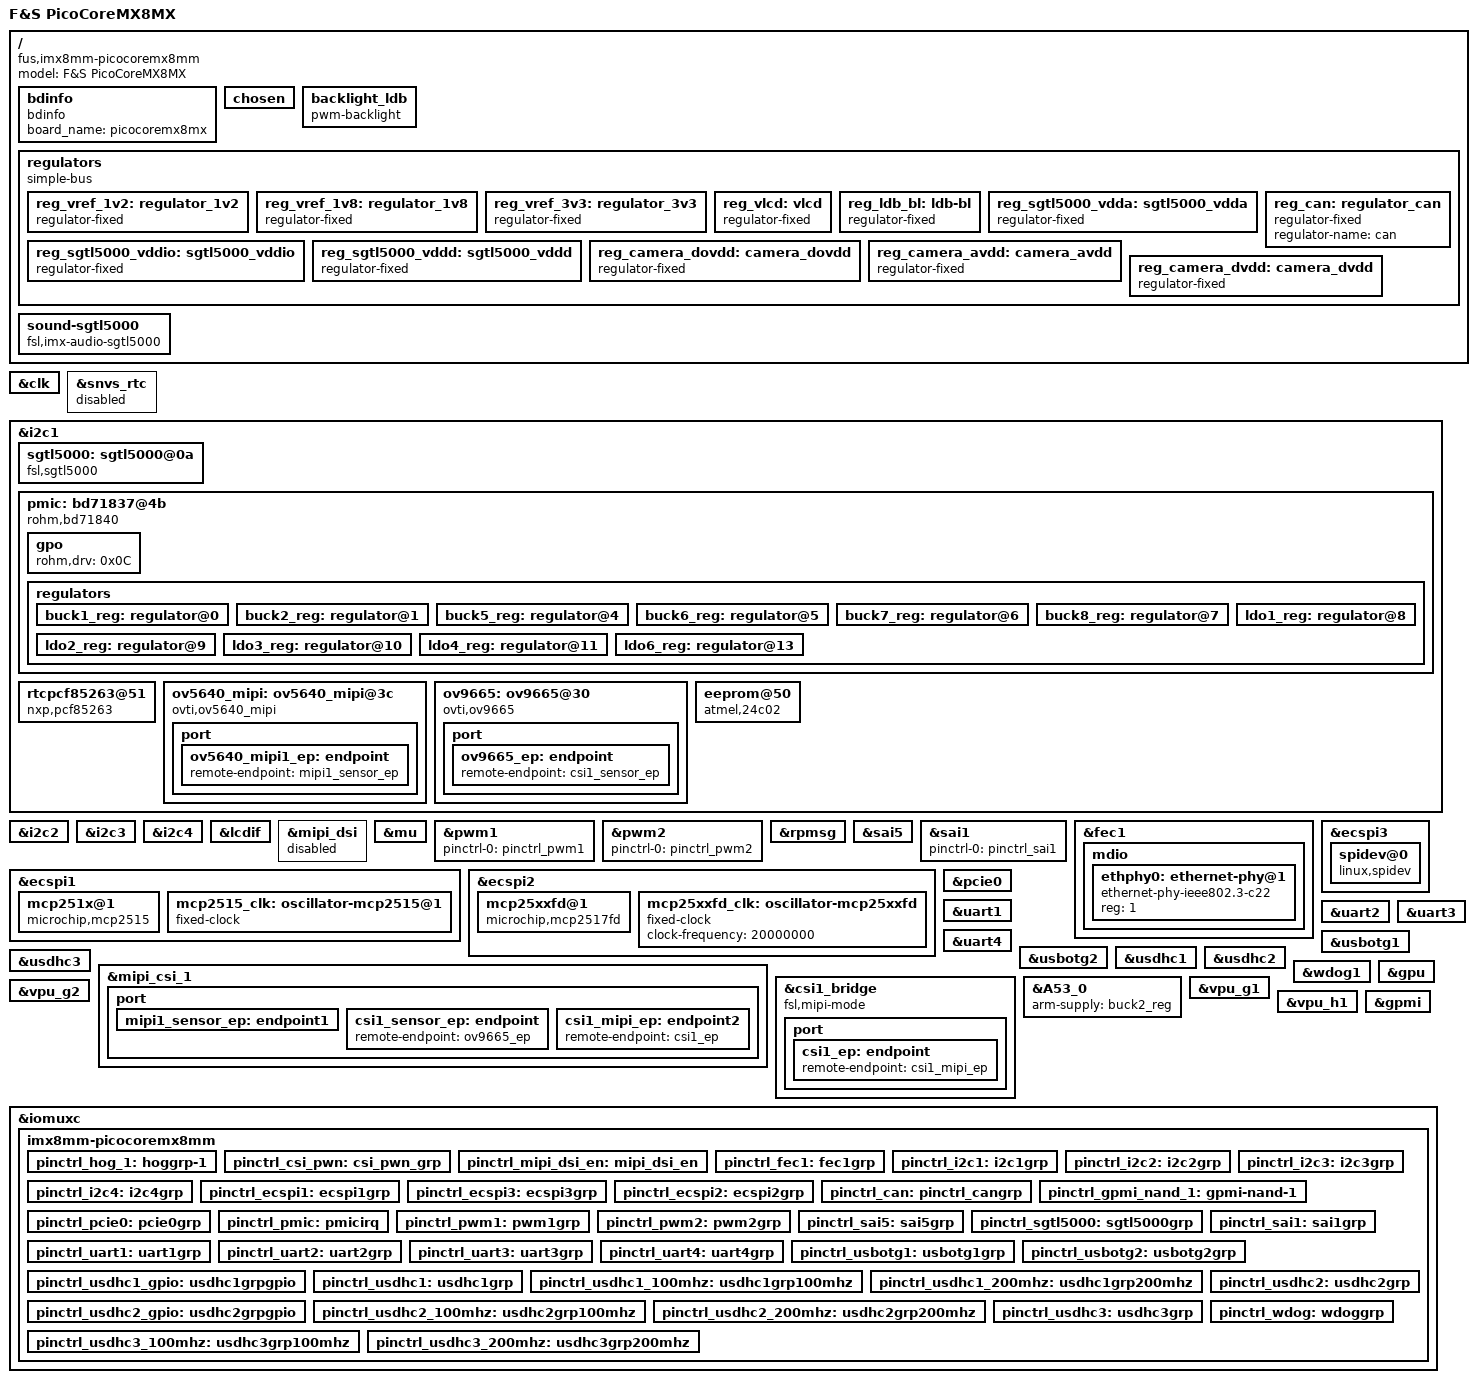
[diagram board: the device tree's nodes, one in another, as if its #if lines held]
/*
 * Copyright 2018 NXP
 *
 * This program is free software; you can redistribute it and/or
 * modify it under the terms of the GNU General Public License
 * as published by the Free Software Foundation; either version 2
 * of the License, or (at your option) any later version.
 *
 * This program is distributed in the hope that it will be useful,
 * but WITHOUT ANY WARRANTY; without even the implied warranty of
 * MERCHANTABILITY or FITNESS FOR A PARTICULAR PURPOSE.  See the
 * GNU General Public License for more details.
 */

/*
 * Copyright (C) 2019 F&S Elektronik Systeme GmbH
 *
 * This program is free software; you can redistribute it and/or modify
 * it under the terms of the GNU General Public License version 2 as
 * published by the Free Software Foundation.
 */

/dts-v1/;

/* Set board revision as 3-digit number, e.g. 110 for board rev. 1.10 */
#define CONFIG_PICOCOREMX8MX_BOARD_REVISION	100

/* MIPI DSI */
#define CONFIG_PICOCOREMX8MX_MIPI_DSI
//#define CONFIG_PICOCOREMX8MX_MIPI_DSI_LVDS

/* On-board NAND */
#define CONFIG_PICOCOREMX8MX_NAND

/* On-board eMMC */
//#define CONFIG_PICOCOREMX8MX_EMMC

/* Network */
//###: TODO Check how it works with Switch
//#define CONFIG_PICOCOREMX8MX_ETH

/* USB */
#define CONFIG_PICOCOREMX8MX_USB_OTG1
#define CONFIG_PICOCOREMX8MX_USB_HOST

/* EEPROM - default not mounted */
//#define CONFIG_PICOCOREMX8MX_EEPROM

/* PCIe */
#define CONFIG_PICOCOREMX8MX_PCIE

/* CAN - default not mounted */
//#define CONFIG_PICOCOREMX8MX_CAN

/* I2C */
#define CONFIG_PICOCOREMX8MX_I2C_A
#define CONFIG_PICOCOREMX8MX_I2C_B
#define CONFIG_PICOCOREMX8MX_I2C_C
#define CONFIG_PICOCOREMX8MX_I2C_D
//#define CONFIG_PICOCOREMX8MX_I2C_D_A71CH

/* PWM and backlight brightness */
#define CONFIG_PICOCOREMX8MX_PWM_A
#define CONFIG_PICOCOREMX8MX_BL_CTRL

/* UART_A - UART1 */
#define CONFIG_PICOCOREMX8MX_UART_A
#define CONFIG_PICOCOREMX8MX_UART_A_RTSCTS

/* UART_B - UART2 */
#define CONFIG_PICOCOREMX8MX_UART_B
#define CONFIG_PICOCOREMX8MX_UART_B_RTSCTS

/* UART_C - UART4 */
#define CONFIG_PICOCOREMX8MX_UART_C

/* UART_D - UART3 */
#define CONFIG_PICOCOREMX8MX_UART_D

#define CONFIG_PICOCOREMX8MX_SPI_A
/* HW option, only works if R89 = mounted, R82 = umounted */
//#define CONFIG_PICOCOREMX8MX_SPI_A_CAN_CONVERTER
#define CONFIG_PICOCOREMX8MX_SPI_B
#define CONFIG_PICOCOREMX8MX_SPI_C

/* Audio */
#define CONFIG_PICOCOREMX8MX_SGTL5000_AUDIO
//#define CONFIG_PICOCOREMX8MX_AUDIO_2

/* External RTC - default not mounted */
//#define CONFIG_PICOCOREMX8MX_EXT_RTC

#define CONFIG_PICOCOREMX8MX_CAMERA

/* Camera on parallel CSI interface */
//#define CONFIG_PICOCOREMX8MX_PARALLEL_CAMERA

/* Camera on serial MIPI CSI interface */
#define CONFIG_PICOCOREMX8MX_SERIAL_CAMERA

/*
 * SD_A - External SD port with Card Detect (CD) and Write Protect (WP)
 * On picocoremx8mm SKIT: external port is Micro-SD card slot with CD but without WP
 */
#define CONFIG_PICOCOREMX8MX_SD_A
#define CONFIG_PICOCOREMX8MX_SD_A_CD
//#define CONFIG_PICOCOREMX8MX_SD_A_WP

/*
 * SD_B - External SD port with Card Detect (CD) and Write Protect (WP)
 * only available if WLAN is not equipped.
 */
#define CONFIG_PICOCOREMX8MX_SD_B
#define CONFIG_PICOCOREMX8MX_SD_B_CD
#define CONFIG_PICOCOREMX8MX_SD_B_WP

/* If NAND is equipped, eMMC is not available */
#ifdef CONFIG_PICOCOREMX8MX_NAND
#undef CONFIG_PICOCOREMX8MX_EMMC
#endif

#ifdef CONFIG_PICOCOREMX8MX_MIPI_DSI_LVDS
#undef CONFIG_PICOCOREMX8MX_SPI_A_CAN_CONVERTER
#endif

#include "../freescale/fsl-imx8mm.dtsi"
#include <dt-bindings/pwm/pwm.h>
#include <dt-bindings/rtc/nxp,pcf85263.h>

/ {
	model = "F&S PicoCoreMX8MX";
	compatible = "fus,imx8mm-picocoremx8mm", "fsl,imx8mm";

	/* -------------------- BOARD INFO -------------------- */
	bdinfo {
		compatible = "bdinfo";
		board_name = "picocoremx8mx";
	};

	chosen {
		bootargs = "console=ttymxc0,115200 earlycon=ec_imx6q,0x30860000,115200";
		stdout-path = &uart1;
	};

#ifdef CONFIG_PICOCOREMX8MX_BL_CTRL
	backlight_ldb {
		compatible = "pwm-backlight";
		#pwm-cells = <3>;
		pwms = <&pwm2 0 3000000 PWM_POLARITY_INVERTED>;
		power-supply = <&reg_ldb_bl>;
		brightness-levels = <0 1 5 10 18 28 41 56
				     73 92 113 137 163 192 222 255>;
		default-brightness-level = <4>;
		fb-names = "mxs-lcdif0";
	};
#endif

	regulators {
		compatible = "simple-bus";
		#address-cells = <1>;
		#size-cells = <0>;

		/* necessary for lcdif-tc35874-j070wvtc0211 */
		reg_vref_1v2: regulator_1v2 {
			compatible = "regulator-fixed";
			regulator-name = "vref-1V2";
			regulator-min-microvolt = <1200000>;
			regulator-max-microvolt = <1200000>;
			regulator-always-on;
		};

		reg_vref_1v8: regulator_1v8 {
			compatible = "regulator-fixed";
			regulator-name = "vref-1V8";
			regulator-min-microvolt = <1800000>;
			regulator-max-microvolt = <1800000>;
			regulator-always-on;
		};

		reg_vref_3v3: regulator_3v3 {
			compatible = "regulator-fixed";
			regulator-name = "vref-3V3";
			regulator-min-microvolt = <3300000>;
			regulator-max-microvolt = <3300000>;
			regulator-always-on;
		};

		/* LCD power on voltage */
		reg_vlcd: vlcd {
			compatible = "regulator-fixed";
			regulator-name = "VLCD";
			gpio = <&gpio5 1 GPIO_ACTIVE_HIGH>;
			regulator-min-microvolt = <3300000>;
			regulator-max-microvolt = <3300000>;
			enable-active-high;
		};

		reg_ldb_bl: ldb-bl {
			compatible = "regulator-fixed";
			regulator-name = "ldb-bl";
			gpio = <&gpio5 3 GPIO_ACTIVE_HIGH>;
			regulator-min-microvolt = <3300000>;
			regulator-max-microvolt = <3300000>;
			enable-active-high;
		};

#if 0
		reg_usb_otg1_vbus: usb_otg1_vbus {
			compatible = "regulator-fixed";
			regulator-name = "usb_otg1_vbus";
			regulator-min-microvolt = <5000000>;
			regulator-max-microvolt = <5000000>;
			gpio = <&gpio1 12 GPIO_ACTIVE_LOW>;
		};
#endif
#if 0
		reg_usb_otg2_vbus: usb_otg2_vbus {
			compatible = "regulator-fixed";
			regulator-name = "usb_otg1_vbus";
			regulator-min-microvolt = <5000000>;
			regulator-max-microvolt = <5000000>;
			gpio = <&gpio1 14 0>;
			enable-active-high;
		};
#endif

#ifdef CONFIG_PICOCOREMX8MX_SGTL5000_AUDIO
		/* SGTL5000 analog voltage */
		reg_sgtl5000_vdda: sgtl5000_vdda {
			compatible = "regulator-fixed";
			regulator-name = "VDDA-supply";
			regulator-min-microvolt = <3000000>;
			regulator-max-microvolt = <3000000>;
			regulator-always-on;
		};

		/* SGTL5000 I/O voltage */
		reg_sgtl5000_vddio: sgtl5000_vddio {
			compatible = "regulator-fixed";
			regulator-name = "VDDIO-supply";
			regulator-min-microvolt = <3300000>;
			regulator-max-microvolt = <3300000>;
			regulator-always-on;
		};

		/* SGTL5000 internal digital voltage */
		reg_sgtl5000_vddd: sgtl5000_vddd {
			compatible = "regulator-fixed";
			regulator-name = "VDDD-supply";
			regulator-min-microvolt = <1500000>;
			regulator-max-microvolt = <1500000>;
			regulator-always-on;
		};
#endif /* CONFIG_PICOCOREMX8MX_SGTL5000_AUDIO */

		/* CAN */
		reg_can: regulator_can {
			compatible = "regulator-fixed";
			regulator-name = "can";
		};

#ifdef CONFIG_PICOCOREMX8MX_CAMERA
		reg_camera_dovdd: camera_dovdd {
			compatible = "regulator-fixed";
			regulator-name = "DOVDD-supply";
			regulator-min-microvolt = <1800000>;
			regulator-max-microvolt = <1800000>;
		};

		reg_camera_avdd: camera_avdd {
			compatible = "regulator-fixed";
			regulator-name = "VAVDD-supply";
			regulator-min-microvolt = <2800000>;
			regulator-max-microvolt = <2800000>;
		};

		reg_camera_dvdd: camera_dvdd {
			compatible = "regulator-fixed";
			regulator-name = "DVDD-supply";
			regulator-min-microvolt = <1500000>;
			regulator-max-microvolt = <1500000>;
		};
#endif /* CONFIG_EFUSA9_CAMERA */
	};

#ifdef CONFIG_PICOCOREMX8MX_SGTL5000_AUDIO
	sound-sgtl5000 {
		compatible = "fsl,imx-audio-sgtl5000";
		cpu-dai = <&sai5>;
		audio-codec = <&sgtl5000>;
		model = "imx-sgtl5000";
		audio-routing =
			"LINE_IN", "Line In Jack",
//###			"MIC_IN", "Mic Jack",
//###			"Line Out Jack", "LINE_OUT",
			"Headphone Jack", "HP_OUT";
	};
#endif

};

&clk {
	assigned-clocks = <&clk IMX8MM_AUDIO_PLL1>, <&clk IMX8MM_AUDIO_PLL2>;
	assigned-clock-rates = <786432000>, <722534400>;
};

#ifdef CONFIG_PICOCOREMX8MX_EXT_RTC
&snvs_rtc {
	status = "disabled";
};
#endif

#ifdef CONFIG_PICOCOREMX8MX_I2C_D
&i2c1 {
	clock-frequency = <100000>;
	pinctrl-names = "default";
	pinctrl-0 = <&pinctrl_i2c1>;
	status = "okay";


#ifdef CONFIG_PICOCOREMX8MX_SGTL5000_AUDIO
	sgtl5000: sgtl5000@0a {
		compatible = "fsl,sgtl5000";
		/* MCLK is needed for i2c sgtl driver */
		pinctrl-names = "default";
		pinctrl-0 = <&pinctrl_sgtl5000>;
		reg = <0x0a>;
		mono2both;
		clocks = <&clk IMX8MM_CLK_SAI5_ROOT>;
		VDDA-supply = <&reg_sgtl5000_vdda>;
		VDDIO-supply = <&reg_sgtl5000_vddio>;
		VDDD-supply = <&reg_sgtl5000_vddd>;
	};
#endif

	/* PMIC */
	pmic: bd71837@4b {
		reg = <0x4b>;
		compatible = "rohm,bd71840", "rohm,bd71837";
		/* PMIC BD71837 PMIC_nINT GPIO3_IO24 */
		pinctrl-0 = <&pinctrl_pmic>;
		gpio_intr = <&gpio1 10 GPIO_ACTIVE_LOW>;

		gpo {
			rohm,drv = <0x0C>;	/* 0b0000_1100 all gpos with cmos output mode */
		};

		regulators {
			#address-cells = <1>;
			#size-cells = <0>;

			bd71837,pmic-buck2-uses-i2c-dvs;
			bd71837,pmic-buck2-dvs-voltage = <1000000>, <900000>, <0>; /* VDD_ARM: Run-Idle */

			buck1_reg: regulator@0 {
				reg = <0>;
				regulator-compatible = "buck1";
				regulator-min-microvolt = <700000>;
				regulator-max-microvolt = <1300000>;
				regulator-boot-on;
				regulator-always-on;
				regulator-ramp-delay = <1250>;
			};

			buck2_reg: regulator@1 {
				reg = <1>;
				regulator-compatible = "buck2";
				regulator-min-microvolt = <700000>;
				regulator-max-microvolt = <1300000>;
				regulator-boot-on;
				regulator-always-on;
				regulator-ramp-delay = <1250>;
			};
#if 0
			buck3_reg: regulator@2 {
				reg = <2>;
				regulator-compatible = "buck3";
				regulator-min-microvolt = <700000>;
				regulator-max-microvolt = <1300000>;
			};

			buck4_reg: regulator@3 {
				reg = <3>;
				regulator-compatible = "buck4";
				regulator-min-microvolt = <700000>;
				regulator-max-microvolt = <1300000>;
			};
#endif
			buck5_reg: regulator@4 {
				reg = <4>;
				regulator-compatible = "buck5";
				regulator-min-microvolt = <700000>;
				regulator-max-microvolt = <1350000>;
				regulator-boot-on;
				regulator-always-on;
			};

			buck6_reg: regulator@5 {
				reg = <5>;
				regulator-compatible = "buck6";
				regulator-min-microvolt = <2600000>;
				regulator-max-microvolt = <3300000>;
				regulator-boot-on;
				regulator-always-on;
			};

			buck7_reg: regulator@6 {
				reg = <6>;
				regulator-compatible = "buck7";
				regulator-min-microvolt = <1500000>;
				regulator-max-microvolt = <1605000>;
				regulator-boot-on;
				regulator-always-on;
			};

			buck8_reg: regulator@7 {
				reg = <7>;
				regulator-compatible = "buck8";
				regulator-min-microvolt = <800000>;
				regulator-max-microvolt = <1400000>;
				regulator-boot-on;
				regulator-always-on;
			};

			ldo1_reg: regulator@8 {
				reg = <8>;
				regulator-compatible = "ldo1";
				regulator-min-microvolt = <1600000>;
				regulator-max-microvolt = <1900000>;
				regulator-boot-on;
				regulator-always-on;
			};

			ldo2_reg: regulator@9 {
				reg = <9>;
				regulator-compatible = "ldo2";
				regulator-min-microvolt = <800000>;
				regulator-max-microvolt = <900000>;
				regulator-boot-on;
				regulator-always-on;
			};

			ldo3_reg: regulator@10 {
				reg = <10>;
				regulator-compatible = "ldo3";
				regulator-min-microvolt = <1800000>;
				regulator-max-microvolt = <3300000>;
				regulator-boot-on;
				regulator-always-on;
			};

			ldo4_reg: regulator@11 {
				reg = <11>;
				regulator-compatible = "ldo4";
				regulator-min-microvolt = <900000>;
				regulator-max-microvolt = <1800000>;
				regulator-boot-on;
				regulator-always-on;
			};

			ldo6_reg: regulator@13 {
				reg = <13>;
				regulator-compatible = "ldo6";
				regulator-min-microvolt = <900000>;
				regulator-max-microvolt = <1800000>;
				regulator-boot-on;
				regulator-always-on;
			};
		};
	};

#ifdef CONFIG_PICOCOREMX8MX_EXT_RTC
	rtcpcf85263@51 {
		compatible = "nxp,pcf85263";
		reg = <0x51>;
		clock-out = <PCF85263_CLK_OUT_32p768kHz>;

		quartz-load-capacitance = <PCF85263_QUARTZCAP_12p5pF>;
		quartz-drive-strength = <PCF85263_QUARTZDRIVE_LOW>;
	};
#endif

#ifdef CONFIG_PICOCOREMX8MX_SERIAL_CAMERA
	ov5640_mipi: ov5640_mipi@3c {
		compatible = "ovti,ov5640_mipi";
		reg = <0x3c>;
		status = "okay";
		pinctrl-names = "default";
		pinctrl-0 = <&pinctrl_csi_pwn>;
		clocks = <&clk IMX8MM_CLK_DUMMY>;
		clock-names = "csi_mclk";
		DOVDD-supply = <&reg_camera_dovdd>; /* 1.8v */
		AVDD-supply = <&reg_camera_avdd>;  /* 2.8v, rev C board is VGEN3
						rev B board is VGEN5 */
		DVDD-supply = <&reg_camera_dvdd>;  /* 1.5v*/
		csi_id = <0>;
		pwn-gpios = <&gpio1 0 GPIO_ACTIVE_LOW>;
		mclk = <24000000>;
		mclk_source = <0>;
		port {
			ov5640_mipi1_ep: endpoint {
				remote-endpoint = <&mipi1_sensor_ep>;
			};
		};
	};
#endif

#ifdef CONFIG_PICOCOREMX8MX_PARALLEL_CAMERA
	ov9665: ov9665@30 {
		compatible = "ovti,ov9665";
		reg = <0x30>;
		pinctrl-names = "default";
		pinctrl-0 = <&pinctrl_csi_pwn>;
		clocks = <&clks IMX8MM_CLK_DUMMY>;
		clock-names = "csi_mclk";
		DOVDD-supply = <&reg_camera_dovdd>;	/* 1.8v */
		AVDD-supply = <&reg_camera_avdd>;	/* 2.8v */
		DVDD-supply = <&reg_camera_dvdd>;	/* 1.5v */
		pwn-gpios = <&gpio1 0 GPIO_ACTIVE_LOW>;
		//rst-gpios = <&gpio3 27 GPIO_ACTIVE_HIGH>;
		csi_id = <0>;
		mclk = <24000000>;
		mclk_source = <0>;
		port {
			ov9665_ep: endpoint {
				remote-endpoint = <&csi1_sensor_ep>;
			};
		};
	};
#endif

#ifdef CONFIG_PICOCOREMX8MX_EEPROM
	/* EEPROM */
	eeprom@50 {
		compatible = "atmel,24c02";
		reg = <0x50>;
		pagesize = <8>;
	};
#endif

	/* ### TODO: implement root of trust A71CH-SDS */
};
#endif

#ifdef CONFIG_PICOCOREMX8MX_I2C_B
&i2c2 {
	clock-frequency = <100000>;
	pinctrl-names = "default";
	pinctrl-0 = <&pinctrl_i2c2>;
	status = "okay";
};
#endif

#ifdef CONFIG_PICOCOREMX8MX_I2C_C
&i2c3 {
	clock-frequency = <100000>;
	pinctrl-names = "default";
	pinctrl-0 = <&pinctrl_i2c3>;
	status = "okay";

	/* PCIe */

};
#endif

#ifdef CONFIG_PICOCOREMX8MX_I2C_A
&i2c4 {
	clock-frequency = <100000>;
	pinctrl-names = "default";
	pinctrl-0 = <&pinctrl_i2c4>;
	status = "okay";
};
#endif

&lcdif {
	status = "okay";
};

#ifdef CONFIG_PICOCOREMX8MX_MIPI_DSI
&mipi_dsi {
	status = "disabled";
};
#endif

&mu {
	status = "okay";
};

#ifdef CONFIG_PICOCOREMX8MX_PWM_A
&pwm1 {
	pinctrl-names = "default";
	pinctrl-0 = <&pinctrl_pwm1>;
	status = "okay";
};
#endif

#ifdef CONFIG_PICOCOREMX8MX_BL_CTRL
&pwm2 {
	pinctrl-names = "default";
	pinctrl-0 = <&pinctrl_pwm2>;
	status = "okay";
};
#endif

&rpmsg{
	/*
	 * 64K for one rpmsg instance:
	 * --0xb8000000~0xb800ffff: pingpong
	 */
	vdev-nums = <1>;
	reg = <0x0 0xb8000000 0x0 0x10000>;
	status = "okay";
};

#ifdef CONFIG_PICOCOREMX8MX_SGTL5000_AUDIO
&sai5 {
	#sound-dai-cells = <0>;
	pinctrl-names = "default";
	pinctrl-0 = <&pinctrl_sai5>;
	assigned-clocks = <&clk IMX8MM_CLK_SAI5>;
	assigned-clock-parents = <&clk IMX8MM_AUDIO_PLL1_OUT>;
	assigned-clock-rates = <24576000>;

	status = "okay";
};

#endif

#ifdef CONFIG_PICOCOREMX8MX_AUDIO_2
&sai1 {
	pinctrl-names = "default";
	pinctrl-0 = <&pinctrl_sai1>;
	status = "okay";
};
#endif

#ifdef CONFIG_PICOCOREMX8MX_ETH
&fec1 {
	pinctrl-names = "default";
	pinctrl-0 = <&pinctrl_fec1>;
	phy-mode = "rgmii-id";
	phy-handle = <&ethphy0>;
	fsl,magic-packet;
	status = "okay";

	mdio {
		#address-cells = <1>;
		#size-cells = <0>;

		ethphy0: ethernet-phy@1 {
			compatible = "ethernet-phy-ieee802.3-c22";
			reg = <1>;
		};
	};
};

#endif

#ifdef CONFIG_PICOCOREMX8MX_SPI_A
&ecspi1 {
	#address-cells = <1>;
	#size-cells = <0>;
	pinctrl-names = "default";
	pinctrl-0 = <&pinctrl_ecspi1>;
	fsl,spi-num-chipselects = <1>;
	cs-gpios = <&gpio5 9 GPIO_ACTIVE_LOW>;
	status = "okay";

#ifdef CONFIG_PICOCOREMX8MX_SPI_A_CAN_CONVERTER
	mcp251x@1 {
		compatible = "microchip,mcp2515";
		reg = <0>;
		clocks = <&mcp2515_clk>;
		interrupt-parent = <&gpio1>;
		interrupts = <4 IRQ_TYPE_EDGE_FALLING>;
		spi-max-frequency = <10000000>;
		status = "okay";
	};

	mcp2515_clk: oscillator-mcp2515@1 {
		compatible = "fixed-clock";
		reg = <1>;
		#clock-cells = <0>;
		clock-frequency = <20000000>; //20MHz
		};
#else
	spidev@0 {
		compatible = "linux,spidev";
		spi-max-frequency = <20000000>;
		reg = <0>;
		status = "okay";
	};
#endif
};
#endif

#ifdef CONFIG_PICOCOREMX8MX_SPI_B
&ecspi3 {
	#address-cells = <1>;
	#size-cells = <0>;
	pinctrl-names = "default";
	pinctrl-0 = <&pinctrl_ecspi3>;
	fsl,spi-num-chipselects = <1>;
	cs-gpios = <&gpio5 25 GPIO_ACTIVE_LOW>;
	status = "okay";

	spidev@0 {
		compatible = "linux,spidev";
		spi-max-frequency = <20000000>;
		reg = <0>;
		status = "okay";
	};
};
#endif

#ifdef CONFIG_PICOCOREMX8MX_SPI_C
&ecspi2 {
	pinctrl-names = "default";
	pinctrl-0 = <&pinctrl_ecspi2>;
	fsl,spi-num-chipselects = <1>;
	cs-gpios = <&gpio5 13 GPIO_ACTIVE_LOW>;
	status = "okay";

#ifdef CONFIG_PICOCOREMX8MX_CAN
	mcp25xxfd@1 {
		compatible = "microchip,mcp2517fd";
		reg = <0>;
		pinctrl-names = "default";
		pinctrl-0 = <&pinctrl_can>;
		spi-max-frequency = <10000000>;
		interrupt-parent = <&gpio4>;
		interrupts = <28 IRQ_TYPE_LEVEL_LOW>;
		clocks = <&mcp25xxfd_clk>;
		xceiver-supply = <&reg_can>;
		status = "okay";
	};
	mcp25xxfd_clk: oscillator-mcp25xxfd {
		compatible = "fixed-clock";
		#clock-cells = <0>;
		clock-frequency = <20000000>; //20MHz
	};
#endif
};
#endif

#ifdef CONFIG_PICOCOREMX8MX_PCIE
&pcie0 {
	pinctrl-names = "default";
	pinctrl-0 = <&pinctrl_pcie0>;
	reset-gpio = <&gpio3 19 GPIO_ACTIVE_LOW>;
	wake-gpio = <&gpio3 20 GPIO_ACTIVE_LOW>;
	ext_osc = <0>;
	status = "okay";
};
#endif

#ifdef CONFIG_PICOCOREMX8MX_UART_A
&uart1 {
	pinctrl-names = "default";
	pinctrl-0 = <&pinctrl_uart1>;
	assigned-clocks = <&clk IMX8MM_CLK_UART1>;
	assigned-clock-parents = <&clk IMX8MM_SYS_PLL1_80M>;
#ifdef CONFIG_PICOCOREMX8MX_UART_A_RTSCTS
	fsl,uart-has-rtscts;
#endif
	status = "okay";
};
#endif

#ifdef CONFIG_PICOCOREMX8MX_UART_B
&uart2 { /* console */
	pinctrl-names = "default";
	pinctrl-0 = <&pinctrl_uart2>;
	assigned-clocks = <&clk IMX8MM_CLK_UART2>;
	assigned-clock-parents = <&clk IMX8MM_SYS_PLL1_80M>;
#ifdef CONFIG_PICOCOREMX8MX_UART_B_RTSCTS
	fsl,uart-has-rtscts;
#endif
	status = "okay";
};
#endif

#ifdef CONFIG_PICOCOREMX8MX_UART_D
&uart3 {
	pinctrl-names = "default";
	pinctrl-0 = <&pinctrl_uart3>;
	assigned-clocks = <&clk IMX8MM_CLK_UART3>;
	assigned-clock-parents = <&clk IMX8MM_SYS_PLL1_80M>;
	status = "okay";
};
#endif

#ifdef CONFIG_PICOCOREMX8MX_UART_C
&uart4 {
	pinctrl-names = "default";
	pinctrl-0 = <&pinctrl_uart4>;
	assigned-clocks = <&clk IMX8MM_CLK_UART4>;
	assigned-clock-parents = <&clk IMX8MM_SYS_PLL1_80M>;
	status = "okay";
};
#endif

#ifdef CONFIG_PICOCOREMX8MX_USB_OTG1
&usbotg1 {
	dr_mode = "otg";
	pinctrl-names = "default";
	pinctrl-0 = <&pinctrl_usbotg1>;
	//vbus-supply = <&reg_usb_otg1_vbus>;
	picophy,pre-emp-curr-control = <3>;
	picophy,dc-vol-level-adjust = <7>;
	disable-over-current;
	status = "okay";
};
#endif

#ifdef CONFIG_PICOCOREMX8MX_USB_HOST
&usbotg2 {
	dr_mode = "host";
	pinctrl-names ="default";
	pinctrl-0 = <&pinctrl_usbotg2>;
	//vbus-supply = <&reg_usb_otg2_vbus>;
	pwr-active-high;
	disable-over-current;
	picophy,pre-emp-curr-control = <3>;
	picophy,dc-vol-level-adjust = <7>;
	status = "okay";
};
#endif

#ifdef CONFIG_PICOCOREMX8MX_SD_A
&usdhc1 {
	pinctrl-names = "default", "state_100mhz", "state_200mhz";
	pinctrl-0 = <&pinctrl_usdhc1>, <&pinctrl_usdhc1_gpio>;
	pinctrl-1 = <&pinctrl_usdhc1_100mhz>, <&pinctrl_usdhc1_gpio>;
	pinctrl-2 = <&pinctrl_usdhc1_200mhz>, <&pinctrl_usdhc1_gpio>;
	bus-width = <4>;
#ifdef CONFIG_PICOCOREMX8MX_SD_A_CD
	cd-gpios = <&gpio1 6 GPIO_ACTIVE_LOW>;
#else
	non-removable;
#endif
#ifdef CONFIG_PICOCOREMX8MX_SD_A_WP
	wp-gpios = <&gpio1 7 GPIO_ACTIVE_HIGH>;
#endif
	vmmc-supply = <&reg_vref_3v3>;
	vqmmc-supply = <&reg_vref_3v3>;
	pm-ignore-notify;
	keep-power-in-suspend;
	status = "okay";
};
#endif

/* WLAN */
#ifdef CONFIG_PICOCOREMX8MX_SD_B
&usdhc2 {
	pinctrl-names = "default", "state_100mhz", "state_200mhz";
	pinctrl-0 = <&pinctrl_usdhc2>, <&pinctrl_usdhc2_gpio>;
	pinctrl-1 = <&pinctrl_usdhc2_100mhz>, <&pinctrl_usdhc2_gpio>;
	pinctrl-2 = <&pinctrl_usdhc2_200mhz>, <&pinctrl_usdhc2_gpio>;
#ifdef CONFIG_PICOCOREMX8MX_SD_B_CD
	cd-gpios = <&gpio2 12 GPIO_ACTIVE_LOW>;
#else
	non-removable;
#endif
#ifdef CONFIG_PICOCOREMX8MX_SD_B_WP
	wp-gpios = <&gpio2 20 GPIO_ACTIVE_HIGH>;
#endif
	bus-width = <4>;
	vmmc-supply = <&reg_vref_3v3>;
	vqmmc-supply = <&reg_vref_3v3>;
	voltage-ranges = <3300 3300>;
	no-1-8-v;
	keep-power-in-suspend;
	status = "okay";
};
#endif

#ifdef CONFIG_PICOCOREMX8MX_EMMC
&usdhc3 {
	pinctrl-names = "default", "state_100mhz", "state_200mhz";
	pinctrl-0 = <&pinctrl_usdhc3>;
	pinctrl-1 = <&pinctrl_usdhc3_100mhz>;
	pinctrl-2 = <&pinctrl_usdhc3_200mhz>;
	bus-width = <8>;
	voltage-ranges = <3300 3300>;
	no-1-8-v;
	non-removable;
	status = "okay";
};
#endif

#ifdef CONFIG_PICOCOREMX8MX_SERIAL_CAMERA
&mipi_csi_1 {
	#address-cells = <1>;
	#size-cells = <0>;
	status = "okay";
	port {
		mipi1_sensor_ep: endpoint1 {
			remote-endpoint = <&ov5640_mipi1_ep>;
			data-lanes = <2>;
			csis-hs-settle = <13>;
			csis-clk-settle = <2>;
			csis-wclk;
		};

#ifdef CONFIG_PICOCOREMX8MX_PARALLEL_CAMERA
		csi1_sensor_ep: endpoint {
			remote-endpoint = <&ov9665_ep>;
		};
#endif

		csi1_mipi_ep: endpoint2 {
			remote-endpoint = <&csi1_ep>;
		};
	};
};

&csi1_bridge {
	fsl,mipi-mode;
	status = "okay";
	port {
		csi1_ep: endpoint {
			remote-endpoint = <&csi1_mipi_ep>;
		};
	};
};
#endif


&wdog1 {
	pinctrl-names = "default";
	pinctrl-0 = <&pinctrl_wdog>;
	fsl,ext-reset-output;
	status = "okay";
};

&A53_0 {
	arm-supply = <&buck2_reg>;
};

&gpu {
	status = "okay";
};

&vpu_g1 {
	status = "okay";
};

&vpu_g2 {
	status = "okay";
};

&vpu_h1 {
	status = "okay";
};

#ifdef CONFIG_PICOCOREMX8MX_NAND
&gpmi {
	pinctrl-names = "default";
	pinctrl-0 = <&pinctrl_gpmi_nand_1>;
	status = "okay";
	nand-on-flash-bbt;
};
#endif

&iomuxc {
	pinctrl-names = "default";

	imx8mm-picocoremx8mm {
		/* Pin configs that don't belong anywhere else */
		pinctrl_hog_1: hoggrp-1 {
			fsl,pins = <
				/* GPIO */
#ifndef CONFIG_PICOCOREMX8MX_MIPI_DSI_LVDS
#ifndef CONFIG_PICOCOREMX8MX_SPI_A_CAN_CONVERTER
				/* GPIO_J1_46 */
				MX8MM_IOMUXC_GPIO1_IO04_GPIO1_IO4		0x00104
#endif
				/* GPIO_J1_52 */
				MX8MM_IOMUXC_GPIO1_IO08_GPIO1_IO8		0x00104
				/* GPIO_J1_54 */
				MX8MM_IOMUXC_GPIO1_IO15_GPIO1_IO15		0x00104
#else
				/* LVDS_STBY */
				MX8MM_IOMUXC_GPIO1_IO04_GPIO1_IO4		0x00104
#endif
#ifndef CONFIG_PICOCOREMX8MX_SERIAL_CAMERA
				/* GPIO_J1_44 */
				MX8MM_IOMUXC_GPIO1_IO00_GPIO1_IO0		0x00104
#endif
#ifndef CONFIG_PICOCOREMX8MX_I2C_D_A71CH
				/* GPIO_J2_67 */
				MX8MM_IOMUXC_GPIO1_IO09_GPIO1_IO9		0x00104
#else
				/* I2C_A71CH_RST - default PD */
				MX8MM_IOMUXC_GPIO1_IO09_GPIO1_IO9		0x00104
#endif
#ifndef CONFIG_PICOCOREMX8MX_ETH
				/* GPIO_J2_77 */
				MX8MM_IOMUXC_GPIO1_IO11_GPIO1_IO11		0x00104
#endif
#ifndef CONFIG_PICOCOREMX8MX_CAN
				/* GPIO_J2_75 */
				MX8MM_IOMUXC_SAI3_RXFS_GPIO4_IO28		0x00104
				/* GPIO_J2_65 */
				MX8MM_IOMUXC_SAI2_MCLK_GPIO4_IO27		0x00104
				/* GPIO_J2_69 */
				MX8MM_IOMUXC_SAI2_TXC_GPIO4_IO25		0x00104
				/* GPIO_J2_73 */
				MX8MM_IOMUXC_SAI2_TXD0_GPIO4_IO26		0x00104
#endif
#ifndef CONFIG_PICOCOREMX8MX_AUDIO_2
				/* GPIO_J2_65 */
				MX8MM_IOMUXC_SAI1_MCLK_GPIO4_IO20		0x00104
				/* GPIO_J2_67 */
				MX8MM_IOMUXC_SAI1_TXFS_GPIO4_IO10		0x00104
				/* GPIO_J2_69 */
				MX8MM_IOMUXC_SAI1_TXC_GPIO4_IO11		0x00104
				/* GPIO_J2_73 */
				MX8MM_IOMUXC_SAI1_TXD0_GPIO4_IO12		0x00104
				/* GPIO_J2_77 */
				MX8MM_IOMUXC_SAI1_RXFS_GPIO4_IO0		0x00104
				/* GPIO_J2_79 */
				MX8MM_IOMUXC_SAI1_RXC_GPIO4_IO1			0x00104
				/* GPIO_J2_75 */
				MX8MM_IOMUXC_SAI1_RXD0_GPIO4_IO2		0x00104
#endif
				/* I2C_B_IRQn */
				MX8MM_IOMUXC_SAI3_MCLK_GPIO5_IO2		0x00144
				/* GPIO_J1_7, MIPI_RESET  */
				MX8MM_IOMUXC_GPIO1_IO01_GPIO1_IO1		0x00144
				/* BL_ON */
				MX8MM_IOMUXC_SPDIF_TX_GPIO5_IO3			0x00104
				/* GPIO_J1_2 */
				MX8MM_IOMUXC_GPIO1_IO13_GPIO1_IO13		0x00104
				/* VLCD_ON */
				MX8MM_IOMUXC_SAI3_TXD_GPIO5_IO1			0x00104
			>;
		};

#ifdef CONFIG_PICOCOREMX8MX_SERIAL_CAMERA
		pinctrl_csi_pwn: csi_pwn_grp {
			fsl,pins = <
				MX8MM_IOMUXC_GPIO1_IO00_GPIO1_IO0		0x00104
			>;
		};
#endif

#ifdef CONFIG_PICOCOREMX8MX_MIPI_DSI_LVDS
		pinctrl_mipi_dsi_en: mipi_dsi_en {
			fsl,pins = <
				/* LVDS RESET / TC358764 RST */
				MX8MM_IOMUXC_GPIO1_IO08_GPIO1_IO8			0x00016
				/* CLKO2 -> EXTCLK */
				MX8MM_IOMUXC_GPIO1_IO15_CCMSRCGPCMIX_CLKO2	0x00059
			>;
		};
#endif

#ifdef CONFIG_PICOCOREMX8MX_ETH
		pinctrl_fec1: fec1grp {
			fsl,pins = <
				MX8MM_IOMUXC_ENET_MDC_ENET1_MDC			0x00003
				MX8MM_IOMUXC_ENET_MDIO_ENET1_MDIO		0x00003
				MX8MM_IOMUXC_ENET_TD3_ENET1_RGMII_TD3		0x0001f
				MX8MM_IOMUXC_ENET_TD2_ENET1_RGMII_TD2		0x0001f
				MX8MM_IOMUXC_ENET_TD1_ENET1_RGMII_TD1		0x0001f
				MX8MM_IOMUXC_ENET_TD0_ENET1_RGMII_TD0		0x0001f
				MX8MM_IOMUXC_ENET_RD3_ENET1_RGMII_RD3		0x00091
				MX8MM_IOMUXC_ENET_RD2_ENET1_RGMII_RD2		0x00091
				MX8MM_IOMUXC_ENET_RD1_ENET1_RGMII_RD1		0x00091
				MX8MM_IOMUXC_ENET_RD0_ENET1_RGMII_RD0		0x00091
				MX8MM_IOMUXC_ENET_TXC_ENET1_RGMII_TXC		0x0001f
				MX8MM_IOMUXC_ENET_RXC_ENET1_RGMII_RXC		0x00091
				MX8MM_IOMUXC_ENET_RX_CTL_ENET1_RGMII_RX_CTL	0x00091
				MX8MM_IOMUXC_ENET_TX_CTL_ENET1_RGMII_TX_CTL	0x0001f
				/* reset */
				MX8MM_IOMUXC_GPIO1_IO05_GPIO1_IO5		0x00019
				/* ETH_SW_INTn */
				MX8MM_IOMUXC_GPIO1_IO11_GPIO1_IO11		0x00019
			>;
		};

#endif

#ifdef CONFIG_PICOCOREMX8MX_I2C_D
		pinctrl_i2c1: i2c1grp {
			fsl,pins = <
				MX8MM_IOMUXC_I2C1_SCL_I2C1_SCL			0x400001c3
				MX8MM_IOMUXC_I2C1_SDA_I2C1_SDA			0x400001c3
			>;
		};
#endif

#ifdef CONFIG_PICOCOREMX8MX_I2C_B
		pinctrl_i2c2: i2c2grp {
			fsl,pins = <
				MX8MM_IOMUXC_I2C2_SCL_I2C2_SCL			0x400001c3
				MX8MM_IOMUXC_I2C2_SDA_I2C2_SDA			0x400001c3
			>;
		};
#endif

#ifdef CONFIG_PICOCOREMX8MX_I2C_C
		pinctrl_i2c3: i2c3grp {
			fsl,pins = <
				MX8MM_IOMUXC_I2C3_SCL_I2C3_SCL			0x400001c3
				MX8MM_IOMUXC_I2C3_SDA_I2C3_SDA			0x400001c3
			>;
		};
#endif

#ifdef CONFIG_PICOCOREMX8MX_I2C_A
		pinctrl_i2c4: i2c4grp {
			fsl,pins = <
				MX8MM_IOMUXC_I2C4_SCL_I2C4_SCL			0x400001c3
				MX8MM_IOMUXC_I2C4_SDA_I2C4_SDA			0x400001c3
			>;
		};
#endif

#ifdef CONFIG_PICOCOREMX8MX_SPI_A
		pinctrl_ecspi1: ecspi1grp {
			fsl,pins = <
				MX8MM_IOMUXC_ECSPI1_SCLK_ECSPI1_SCLK		0x00082
				MX8MM_IOMUXC_ECSPI1_MOSI_ECSPI1_MOSI		0x00082
				MX8MM_IOMUXC_ECSPI1_MISO_ECSPI1_MISO		0x00082
				MX8MM_IOMUXC_ECSPI1_SS0_GPIO5_IO9			0x40000
#ifdef CONFIG_PICOCOREMX8MX_SPI_A_CAN_CONVERTER
				MX8MM_IOMUXC_GPIO1_IO04_GPIO1_IO4			0x00144
#endif
			>;
		};
#endif

#ifdef CONFIG_PICOCOREMX8MX_SPI_B
		pinctrl_ecspi3: ecspi3grp {
			fsl,pins = <
				MX8MM_IOMUXC_UART1_RXD_ECSPI3_SCLK			0x00082
				MX8MM_IOMUXC_UART1_TXD_ECSPI3_MOSI			0x00082
				MX8MM_IOMUXC_UART2_RXD_ECSPI3_MISO			0x00082
				MX8MM_IOMUXC_UART2_TXD_GPIO5_IO25			0x40000
			>;
		};
#endif

#ifdef CONFIG_PICOCOREMX8MX_SPI_C
		pinctrl_ecspi2: ecspi2grp {
			fsl,pins = <
				MX8MM_IOMUXC_ECSPI2_SCLK_ECSPI2_SCLK		0x00082
				MX8MM_IOMUXC_ECSPI2_MOSI_ECSPI2_MOSI		0x00082
				MX8MM_IOMUXC_ECSPI2_MISO_ECSPI2_MISO		0x00082
				MX8MM_IOMUXC_ECSPI2_SS0_GPIO5_IO13			0x00144
			>;
		};
#endif

#ifdef CONFIG_PICOCOREMX8MX_CAN
		pinctrl_can: pinctrl_cangrp {
			fsl,pins = <
				/* CAN_CLK0/SOF */
				MX8MM_IOMUXC_SAI2_MCLK_GPIO4_IO27		0x00004
				/* CAN_INTn */
				//MX8MM_IOMUXC_SAI3_RXFS_GPIO4_IO28		0x00144
				MX8MM_IOMUXC_SAI3_RXFS_GPIO4_IO28		0x00019
				/* CAN_INT0n */
				MX8MM_IOMUXC_SAI2_TXC_GPIO4_IO25		0x00004
				/* CAN_INT1n */
				MX8MM_IOMUXC_SAI2_TXD0_GPIO4_IO26		0x00004
			>;
		};
#endif

#ifdef CONFIG_PICOCOREMX8MX_NAND
		pinctrl_gpmi_nand_1: gpmi-nand-1 {
			fsl,pins = <
				MX8MM_IOMUXC_NAND_ALE_RAWNAND_ALE			0x00096
				MX8MM_IOMUXC_NAND_CE0_B_RAWNAND_CE0_B		0x00096
				MX8MM_IOMUXC_NAND_CLE_RAWNAND_CLE			0x00096
				MX8MM_IOMUXC_NAND_DATA00_RAWNAND_DATA00		0x00096
				MX8MM_IOMUXC_NAND_DATA01_RAWNAND_DATA01		0x00096
				MX8MM_IOMUXC_NAND_DATA02_RAWNAND_DATA02		0x00096
				MX8MM_IOMUXC_NAND_DATA03_RAWNAND_DATA03		0x00096
				MX8MM_IOMUXC_NAND_DATA04_RAWNAND_DATA04		0x00096
				MX8MM_IOMUXC_NAND_DATA05_RAWNAND_DATA05		0x00096
				MX8MM_IOMUXC_NAND_DATA06_RAWNAND_DATA06		0x00096
				MX8MM_IOMUXC_NAND_DATA07_RAWNAND_DATA07		0x00096
				MX8MM_IOMUXC_NAND_RE_B_RAWNAND_RE_B			0x00096
				MX8MM_IOMUXC_NAND_READY_B_RAWNAND_READY_B	0x00056
				MX8MM_IOMUXC_NAND_WE_B_RAWNAND_WE_B			0x00096
				MX8MM_IOMUXC_NAND_WP_B_RAWNAND_WP_B			0x00096
			>;
		};
#endif

#ifdef CONFIG_PICOCOREMX8MX_PCIE
		pinctrl_pcie0: pcie0grp {
			fsl,pins = <
				/* mPCIE_PERST */
				MX8MM_IOMUXC_SAI5_RXFS_GPIO3_IO19			0x00041
				/* mPCIE_WAKE */
				MX8MM_IOMUXC_SAI5_RXC_GPIO3_IO20			0x00041
			>;
		};
#endif

		pinctrl_pmic: pmicirq {
			fsl,pins = <
				MX8MM_IOMUXC_GPIO1_IO10_GPIO1_IO10		0x00041
			>;
		};

#ifdef CONFIG_PICOCOREMX8MX_PWM_A
		pinctrl_pwm1: pwm1grp {
			fsl,pins = <
				MX8MM_IOMUXC_SPDIF_EXT_CLK_PWM1_OUT		0x00104
			>;
		};
#endif

#ifdef CONFIG_PICOCOREMX8MX_BL_CTRL
		pinctrl_pwm2: pwm2grp {
			fsl,pins = <
				MX8MM_IOMUXC_SPDIF_RX_PWM2_OUT			0x00104
			>;
		};
#endif

#ifdef CONFIG_PICOCOREMX8MX_SGTL5000_AUDIO
		pinctrl_sai5: sai5grp {
			fsl,pins = <
				MX8MM_IOMUXC_SAI5_RXD1_SAI5_TX_SYNC		0x000d6
				MX8MM_IOMUXC_SAI5_RXD2_SAI5_TX_BCLK		0x000d6
				MX8MM_IOMUXC_SAI5_RXD3_SAI5_TX_DATA0	0x000d6
				MX8MM_IOMUXC_SAI5_RXD0_SAI5_RX_DATA0	0x000d6
			>;
		};

		pinctrl_sgtl5000: sgtl5000grp {
			fsl,pins = <
				MX8MM_IOMUXC_SAI5_MCLK_SAI5_MCLK		0x000d6
			>;
		};
#endif

#ifdef CONFIG_PICOCOREMX8MX_AUDIO_2
		pinctrl_sai1: sai1grp {
			fsl,pins = <
				MX8MM_IOMUXC_SAI1_MCLK_SAI1_MCLK		0x000d6
				MX8MM_IOMUXC_SAI1_TXFS_SAI1_TX_SYNC		0x000d6
				MX8MM_IOMUXC_SAI1_RXD0_SAI1_RX_DATA0	0x000d6
				MX8MM_IOMUXC_SAI1_RXFS_SAI1_RX_SYNC		0x000d6
				MX8MM_IOMUXC_SAI1_TXC_SAI1_TX_BCLK		0x000d6
				MX8MM_IOMUXC_SAI1_TXD0_SAI1_TX_DATA0	0x000d6
				MX8MM_IOMUXC_SAI1_RXC_SAI1_RX_BCLK		0x000d6
			>;
		};
#endif

#ifdef CONFIG_PICOCOREMX8MX_UART_A
		pinctrl_uart1: uart1grp {
			fsl,pins = <
				MX8MM_IOMUXC_SAI2_RXC_UART1_RX			0x00140
				MX8MM_IOMUXC_SAI2_RXFS_UART1_TX			0x00140
#ifdef CONFIG_PICOCOREMX8MX_UART_A_RTSCTS
				/* CTS */
				MX8MM_IOMUXC_SAI2_RXD0_UART1_CTS_B		0x00140
				/* RTS */
				MX8MM_IOMUXC_SAI2_TXFS_UART1_RTS_B		0x00140
#endif
			>;
		};
#endif

#ifdef CONFIG_PICOCOREMX8MX_UART_B
        /* debug output */
		pinctrl_uart2: uart2grp {
			fsl,pins = <
				MX8MM_IOMUXC_SAI3_TXFS_UART2_RX			0x00140
				MX8MM_IOMUXC_SAI3_TXC_UART2_TX			0x00140
#ifdef CONFIG_PICOCOREMX8MX_UART_B_RTSCTS
				/* UART_B_CTS */
				MX8MM_IOMUXC_SAI3_RXC_UART2_CTS_B		0x00140
				/* UART_B_RTS */
				MX8MM_IOMUXC_SAI3_RXD_UART2_RTS_B		0x00140
#endif
			>;
		};
#endif

#ifdef CONFIG_PICOCOREMX8MX_UART_D
		pinctrl_uart3: uart3grp {
			fsl,pins = <
				MX8MM_IOMUXC_UART3_RXD_UART3_DCE_RX		0x00140
				MX8MM_IOMUXC_UART3_TXD_UART3_DCE_TX		0x00140
			>;
		};
#endif

#ifdef CONFIG_PICOCOREMX8MX_UART_C
		pinctrl_uart4: uart4grp {
			fsl,pins = <
				MX8MM_IOMUXC_UART4_RXD_UART4_DCE_RX		0x00140
				MX8MM_IOMUXC_UART4_TXD_UART4_DCE_TX		0x00140
			>;
		};
#endif

#ifdef CONFIG_PICOCOREMX8MX_USB_OTG1
		pinctrl_usbotg1: usbotg1grp {
			fsl,pins = <
				//MX8MM_IOMUXC_GPIO1_IO12_GPIO1_IO12		0x00144
				MX8MM_IOMUXC_GPIO1_IO12_USB1_OTG_PWR	0x00144
			>;
		};
#endif

#ifdef CONFIG_PICOCOREMX8MX_USB_HOST
		pinctrl_usbotg2: usbotg2grp {
			fsl,pins = <
//				MX8MM_IOMUXC_GPIO1_IO14_GPIO1_IO14		0x00144
				MX8MM_IOMUXC_GPIO1_IO14_USB2_OTG_PWR	0x00104
			>;
		};
#endif

#ifdef CONFIG_PICOCOREMX8MX_SD_A
		pinctrl_usdhc1_gpio: usdhc1grpgpio {
			fsl,pins = <
				/* SD_A_VSEL, 3,3V = PD, 1.8 = PU */
				///MX8MM_IOMUXC_GPIO1_IO03_GPIO1_IO3		0x00041
				//MX8MM_IOMUXC_GPIO1_IO03_GPIO1_IO3		0x00141
				MX8MM_IOMUXC_GPIO1_IO03_USDHC1_VSELECT	0x001d0
				/* RESET, high active */
				MX8MM_IOMUXC_SD1_RESET_B_GPIO2_IO10		0x00041
				//MX8MM_IOMUXC_SD1_RESET_B_GPIO2_IO10		0x00141
				/* CD */
				MX8MM_IOMUXC_GPIO1_IO06_GPIO1_IO6		0x001c4
				/* WP */
				MX8MM_IOMUXC_GPIO1_IO07_GPIO1_IO7		0x001c4
			>;
		};

		pinctrl_usdhc1: usdhc1grp {
			fsl,pins = <
				MX8MM_IOMUXC_SD1_CLK_USDHC1_CLK			0x00190
				MX8MM_IOMUXC_SD1_CMD_USDHC1_CMD			0x001d0
				MX8MM_IOMUXC_SD1_DATA0_USDHC1_DATA0		0x001d0
				MX8MM_IOMUXC_SD1_DATA1_USDHC1_DATA1		0x001d0
				MX8MM_IOMUXC_SD1_DATA2_USDHC1_DATA2		0x001d0
				MX8MM_IOMUXC_SD1_DATA3_USDHC1_DATA3		0x001d0
				MX8MM_IOMUXC_SD1_DATA4_USDHC1_DATA4		0x001d0
				MX8MM_IOMUXC_SD1_DATA5_USDHC1_DATA5		0x001d0
				MX8MM_IOMUXC_SD1_DATA6_USDHC1_DATA6		0x001d0
				MX8MM_IOMUXC_SD1_DATA7_USDHC1_DATA7		0x001d0
			>;
		};

		pinctrl_usdhc1_100mhz: usdhc1grp100mhz {
			fsl,pins = <
				MX8MM_IOMUXC_SD1_CLK_USDHC1_CLK			0x00194
				MX8MM_IOMUXC_SD1_CMD_USDHC1_CMD			0x001d4
				MX8MM_IOMUXC_SD1_DATA0_USDHC1_DATA0		0x001d4
				MX8MM_IOMUXC_SD1_DATA1_USDHC1_DATA1		0x001d4
				MX8MM_IOMUXC_SD1_DATA2_USDHC1_DATA2		0x001d4
				MX8MM_IOMUXC_SD1_DATA3_USDHC1_DATA3		0x001d4
				MX8MM_IOMUXC_SD1_DATA4_USDHC1_DATA4		0x001d4
				MX8MM_IOMUXC_SD1_DATA5_USDHC1_DATA5		0x001d4
				MX8MM_IOMUXC_SD1_DATA6_USDHC1_DATA6		0x001d4
				MX8MM_IOMUXC_SD1_DATA7_USDHC1_DATA7		0x001d4
			>;
		};

		pinctrl_usdhc1_200mhz: usdhc1grp200mhz {
			fsl,pins = <
				MX8MM_IOMUXC_SD1_CLK_USDHC1_CLK			0x00196
				MX8MM_IOMUXC_SD1_CMD_USDHC1_CMD			0x001d6
				MX8MM_IOMUXC_SD1_DATA0_USDHC1_DATA0		0x001d6
				MX8MM_IOMUXC_SD1_DATA1_USDHC1_DATA1		0x001d6
				MX8MM_IOMUXC_SD1_DATA2_USDHC1_DATA2		0x001d6
				MX8MM_IOMUXC_SD1_DATA3_USDHC1_DATA3		0x001d6
				MX8MM_IOMUXC_SD1_DATA4_USDHC1_DATA4		0x001d6
				MX8MM_IOMUXC_SD1_DATA5_USDHC1_DATA5		0x001d6
				MX8MM_IOMUXC_SD1_DATA6_USDHC1_DATA6		0x001d6
				MX8MM_IOMUXC_SD1_DATA7_USDHC1_DATA7		0x001d6
			>;
		};
#endif

#ifdef CONFIG_PICOCOREMX8MX_SD_B
		pinctrl_usdhc2_gpio: usdhc2grpgpio {
			fsl,pins = <
#ifdef CONFIG_PICOCOREMX8MX_SD_B_CD
				/* CD */
				MX8MM_IOMUXC_SD2_CD_B_GPIO2_IO12		0x001c4
#endif
#ifdef CONFIG_PICOCOREMX8MX_SD_B_WP
				/* WP */
				MX8MM_IOMUXC_SD2_WP_GPIO2_IO20			0x001c4
#endif
				/* RST */
				MX8MM_IOMUXC_SD2_RESET_B_GPIO2_IO19		0x00041
			>;
		};

		pinctrl_usdhc2: usdhc2grp {
			fsl,pins = <
				MX8MM_IOMUXC_SD2_CLK_USDHC2_CLK			0x00190
				MX8MM_IOMUXC_SD2_CMD_USDHC2_CMD			0x001d0
				MX8MM_IOMUXC_SD2_DATA0_USDHC2_DATA0		0x001d0
				MX8MM_IOMUXC_SD2_DATA1_USDHC2_DATA1		0x001d0
				MX8MM_IOMUXC_SD2_DATA2_USDHC2_DATA2		0x001d0
				MX8MM_IOMUXC_SD2_DATA3_USDHC2_DATA3		0x001d0
			>;
		};

		pinctrl_usdhc2_100mhz: usdhc2grp100mhz {
			fsl,pins = <
				MX8MM_IOMUXC_SD2_CLK_USDHC2_CLK			0x00194
				MX8MM_IOMUXC_SD2_CMD_USDHC2_CMD			0x001d4
				MX8MM_IOMUXC_SD2_DATA0_USDHC2_DATA0		0x001d4
				MX8MM_IOMUXC_SD2_DATA1_USDHC2_DATA1		0x001d4
				MX8MM_IOMUXC_SD2_DATA2_USDHC2_DATA2		0x001d4
				MX8MM_IOMUXC_SD2_DATA3_USDHC2_DATA3		0x001d4
			>;
		};

		pinctrl_usdhc2_200mhz: usdhc2grp200mhz {
			fsl,pins = <
				MX8MM_IOMUXC_SD2_CLK_USDHC2_CLK			0x00196
				MX8MM_IOMUXC_SD2_CMD_USDHC2_CMD			0x001d6
				MX8MM_IOMUXC_SD2_DATA0_USDHC2_DATA0		0x001d6
				MX8MM_IOMUXC_SD2_DATA1_USDHC2_DATA1		0x001d6
				MX8MM_IOMUXC_SD2_DATA2_USDHC2_DATA2		0x001d6
				MX8MM_IOMUXC_SD2_DATA3_USDHC2_DATA3		0x001d6
			>;
		};
#endif

#ifdef CONFIG_PICOCOREMX8MX_EMMC
		pinctrl_usdhc3: usdhc3grp {
			fsl,pins = <
				MX8MM_IOMUXC_NAND_WE_B_USDHC3_CLK		0x00190
				MX8MM_IOMUXC_NAND_WP_B_USDHC3_CMD		0x001d0
				MX8MM_IOMUXC_NAND_DATA04_USDHC3_DATA0	0x001d0
				MX8MM_IOMUXC_NAND_DATA05_USDHC3_DATA1	0x001d0
				MX8MM_IOMUXC_NAND_DATA06_USDHC3_DATA2	0x001d0
				MX8MM_IOMUXC_NAND_DATA07_USDHC3_DATA3	0x001d0
				MX8MM_IOMUXC_NAND_RE_B_USDHC3_DATA4		0x001d0
				MX8MM_IOMUXC_NAND_CE2_B_USDHC3_DATA5	0x001d0
				MX8MM_IOMUXC_NAND_CE3_B_USDHC3_DATA6	0x001d0
				MX8MM_IOMUXC_NAND_CLE_USDHC3_DATA7		0x001d0
				MX8MM_IOMUXC_NAND_CE1_B_USDHC3_STROBE 	0x00190
				/* NAND READY -> RESET */
				MX8MM_IOMUXC_NAND_READY_B_GPIO3_IO16	0x00144
			>;
		};

		pinctrl_usdhc3_100mhz: usdhc3grp100mhz {
			fsl,pins = <
				MX8MM_IOMUXC_NAND_WE_B_USDHC3_CLK		0x00194
				MX8MM_IOMUXC_NAND_WP_B_USDHC3_CMD		0x001d4
				MX8MM_IOMUXC_NAND_DATA04_USDHC3_DATA0	0x001d4
				MX8MM_IOMUXC_NAND_DATA05_USDHC3_DATA1	0x001d4
				MX8MM_IOMUXC_NAND_DATA06_USDHC3_DATA2	0x001d4
				MX8MM_IOMUXC_NAND_DATA07_USDHC3_DATA3	0x001d4
				MX8MM_IOMUXC_NAND_RE_B_USDHC3_DATA4		0x001d4
				MX8MM_IOMUXC_NAND_CE2_B_USDHC3_DATA5	0x001d4
				MX8MM_IOMUXC_NAND_CE3_B_USDHC3_DATA6	0x001d4
				MX8MM_IOMUXC_NAND_CLE_USDHC3_DATA7		0x001d4
				MX8MM_IOMUXC_NAND_CE1_B_USDHC3_STROBE 	0x00194
				/* NAND READY -> RESET */
				MX8MM_IOMUXC_NAND_READY_B_GPIO3_IO16	0x00144
			>;
		};

		pinctrl_usdhc3_200mhz: usdhc3grp200mhz {
			fsl,pins = <
				MX8MM_IOMUXC_NAND_WE_B_USDHC3_CLK		0x00196
				MX8MM_IOMUXC_NAND_WP_B_USDHC3_CMD		0x001d6
				MX8MM_IOMUXC_NAND_DATA04_USDHC3_DATA0	0x001d6
				MX8MM_IOMUXC_NAND_DATA05_USDHC3_DATA1	0x001d6
				MX8MM_IOMUXC_NAND_DATA06_USDHC3_DATA2	0x001d6
				MX8MM_IOMUXC_NAND_DATA07_USDHC3_DATA3	0x001d6
				MX8MM_IOMUXC_NAND_RE_B_USDHC3_DATA4		0x001d6
				MX8MM_IOMUXC_NAND_CE2_B_USDHC3_DATA5	0x001d6
				MX8MM_IOMUXC_NAND_CE3_B_USDHC3_DATA6	0x001d6
				MX8MM_IOMUXC_NAND_CLE_USDHC3_DATA7		0x001d6
				MX8MM_IOMUXC_NAND_CE1_B_USDHC3_STROBE 	0x00196
				/* NAND READY -> RESET */
				MX8MM_IOMUXC_NAND_READY_B_GPIO3_IO16	0x00144
			>;
		};
#endif

		pinctrl_wdog: wdoggrp {
			fsl,pins = <
				MX8MM_IOMUXC_GPIO1_IO02_WDOG1_WDOG_B	0x000c6
			>;
		};

	};
};
